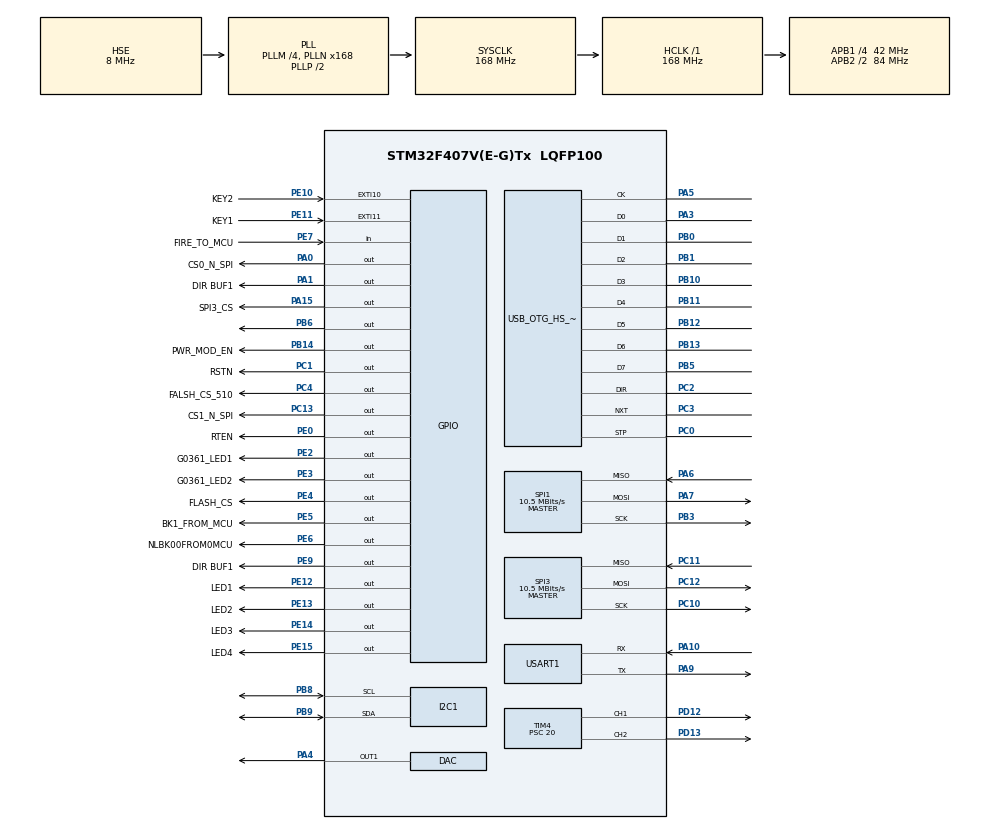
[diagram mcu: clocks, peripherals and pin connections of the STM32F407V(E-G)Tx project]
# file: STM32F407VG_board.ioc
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DAC.DAC_OutputBuffer=DAC_OUTPUTBUFFER_DISABLE
Dma.Request0=SPI1_RX
Dma.Request1=SPI1_TX
Dma.SPI1_RX.0.Direction=DMA_PERIPH_TO_MEMORY
Dma.SPI1_RX.0.FIFOMode=DMA_FIFOMODE_DISABLE
Dma.SPI1_RX.0.Instance=DMA2_Stream2
Dma.SPI1_RX.0.MemDataAlignment=DMA_MDATAALIGN_BYTE
Dma.SPI1_RX.0.MemInc=DMA_MINC_ENABLE
Dma.SPI1_RX.0.Mode=DMA_NORMAL
Dma.SPI1_RX.0.PeriphDataAlignment=DMA_PDATAALIGN_BYTE
Dma.SPI1_RX.0.PeriphInc=DMA_PINC_DISABLE
Dma.SPI1_RX.0.Priority=DMA_PRIORITY_MEDIUM
Dma.SPI1_TX.1.Direction=DMA_MEMORY_TO_PERIPH
Dma.SPI1_TX.1.FIFOMode=DMA_FIFOMODE_DISABLE
Dma.SPI1_TX.1.Instance=DMA2_Stream3
Dma.SPI1_TX.1.MemDataAlignment=DMA_MDATAALIGN_BYTE
Dma.SPI1_TX.1.MemInc=DMA_MINC_ENABLE
Dma.SPI1_TX.1.Mode=DMA_NORMAL
Dma.SPI1_TX.1.PeriphDataAlignment=DMA_PDATAALIGN_BYTE
Dma.SPI1_TX.1.PeriphInc=DMA_PINC_DISABLE
Dma.SPI1_TX.1.Priority=DMA_PRIORITY_MEDIUM
I2C1.I2C_Mode=I2C_Fast
I2C1.OwnAddress=15
IWDG.Prescaler=IWDG_PRESCALER_32
IWDG.Reload=4000
Mcu.Family=STM32F4
Mcu.Name=STM32F407V(E-G)Tx
Mcu.Package=LQFP100
NVIC.DMA2_Stream2_IRQn=true\:0\:0\:false\:false\:true\:false\:true
NVIC.DMA2_Stream3_IRQn=true\:0\:0\:false\:false\:true\:false\:true
NVIC.EXTI15_10_IRQn=true\:4\:0\:true\:false\:true\:true\:true
NVIC.OTG_HS_EP1_IN_IRQn=true\:0\:0\:false\:false\:true\:true\:true
NVIC.OTG_HS_EP1_OUT_IRQn=true\:0\:0\:false\:false\:true\:true\:true
NVIC.OTG_HS_IRQn=true\:0\:0\:false\:false\:true\:false\:true
NVIC.PriorityGroup=NVIC_PRIORITYGROUP_4
NVIC.TIM3_IRQn=true\:0\:0\:false\:false\:true\:true\:true
PA0-WKUP.GPIO_Label=CS0_N_SPI
PA0-WKUP.GPIO_PuPd=GPIO_PULLUP
PA0-WKUP.GPIO_Speed=GPIO_SPEED_FREQ_VERY_HIGH
PA0-WKUP.PinState=GPIO_PIN_SET
PA0-WKUP.Signal=GPIO_Output
PA1.GPIO_Label=DIR BUF1
PA1.GPIO_ModeDefaultOutputPP=GPIO_MODE_OUTPUT_PP
PA1.GPIO_PuPd=GPIO_PULLUP
PA1.GPIO_Speed=GPIO_SPEED_FREQ_VERY_HIGH
PA1.PinState=GPIO_PIN_SET
PA1.Signal=GPIO_Output
PA10.GPIO_Speed=GPIO_SPEED_FREQ_HIGH
PA10.Mode=Asynchronous
PA10.Signal=USART1_RX
PA13.Signal=SYS_JTMS-SWDIO
PA14.Signal=SYS_JTCK-SWCLK
PA15.GPIO_Label=SPI3_CS
PA15.GPIO_PuPd=GPIO_PULLUP
PA15.GPIO_Speed=GPIO_SPEED_FREQ_VERY_HIGH
PA15.PinState=GPIO_PIN_SET
PA15.Signal=GPIO_Output
PA3.Mode=Device_HS
PA3.Signal=USB_OTG_HS_ULPI_D0
PA4.Signal=COMP_DAC1_group
PA5.Mode=Device_HS
PA5.Signal=USB_OTG_HS_ULPI_CK
PA6.GPIO_PuPd=GPIO_PULLUP
PA6.Mode=Full_Duplex_Master
PA6.Signal=SPI1_MISO
PA7.GPIO_PuPd=GPIO_PULLUP
PA7.Mode=Full_Duplex_Master
PA7.Signal=SPI1_MOSI
PA9.GPIO_Speed=GPIO_SPEED_FREQ_HIGH
PA9.Mode=Asynchronous
PA9.Signal=USART1_TX
PB0.Mode=Device_HS
PB0.Signal=USB_OTG_HS_ULPI_D1
PB1.Mode=Device_HS
PB1.Signal=USB_OTG_HS_ULPI_D2
PB10.Mode=Device_HS
PB10.Signal=USB_OTG_HS_ULPI_D3
PB11.Mode=Device_HS
PB11.Signal=USB_OTG_HS_ULPI_D4
PB12.Mode=Device_HS
PB12.Signal=USB_OTG_HS_ULPI_D5
PB13.Mode=Device_HS
PB13.Signal=USB_OTG_HS_ULPI_D6
PB14.GPIO_Label=PWR_MOD_EN
PB14.GPIO_PuPd=GPIO_PULLUP
PB14.GPIO_Speed=GPIO_SPEED_FREQ_VERY_HIGH
PB14.Signal=GPIO_Output
PB3.GPIO_PuPd=GPIO_PULLUP
PB3.Mode=Full_Duplex_Master
PB3.Signal=SPI1_SCK
PB5.Mode=Device_HS
PB5.Signal=USB_OTG_HS_ULPI_D7
PB6.GPIO_ModeDefaultOutputPP=GPIO_MODE_OUTPUT_OD
PB6.GPIO_Speed=GPIO_SPEED_FREQ_VERY_HIGH
PB6.Signal=GPIO_Output
PB8.GPIO_PuPdOD=GPIO_NOPULL
PB8.GPIO_Speed=GPIO_SPEED_FREQ_HIGH
PB8.Mode=I2C
PB8.Signal=I2C1_SCL
PB9.GPIO_PuPdOD=GPIO_NOPULL
PB9.GPIO_Speed=GPIO_SPEED_FREQ_HIGH
PB9.Mode=I2C
PB9.Signal=I2C1_SDA
PC0.Mode=Device_HS
PC0.Signal=USB_OTG_HS_ULPI_STP
PC1.GPIO_Label=RSTN
PC1.GPIO_PuPd=GPIO_PULLUP
PC1.GPIO_Speed=GPIO_SPEED_FREQ_VERY_HIGH
PC1.PinState=GPIO_PIN_SET
PC1.Signal=GPIO_Output
PC10.GPIO_PuPd=GPIO_PULLUP
PC10.Mode=Full_Duplex_Master
PC10.Signal=SPI3_SCK
PC11.GPIO_PuPd=GPIO_PULLUP
PC11.Mode=Full_Duplex_Master
PC11.Signal=SPI3_MISO
PC12.GPIO_PuPd=GPIO_PULLUP
PC12.Mode=Full_Duplex_Master
PC12.Signal=SPI3_MOSI
PC13-ANTI_TAMP.GPIO_Label=CS1_N_SPI
PC13-ANTI_TAMP.GPIO_PuPd=GPIO_PULLUP
PC13-ANTI_TAMP.PinState=GPIO_PIN_SET
PC13-ANTI_TAMP.Signal=GPIO_Output
PC2.Mode=Device_HS
PC2.Signal=USB_OTG_HS_ULPI_DIR
PC3.Mode=Device_HS
PC3.Signal=USB_OTG_HS_ULPI_NXT
PC4.GPIO_Label=FALSH_CS_510
PC4.GPIO_PuPd=GPIO_PULLUP
PC4.GPIO_Speed=GPIO_SPEED_FREQ_VERY_HIGH
PC4.PinState=GPIO_PIN_SET
PC4.Signal=GPIO_Output
PD12.GPIO_PuPd=GPIO_PULLDOWN
PD12.GPIO_Speed=GPIO_SPEED_FREQ_VERY_HIGH
PD12.Signal=S_TIM4_CH1
PD13.GPIO_PuPd=GPIO_PULLDOWN
PD13.GPIO_Speed=GPIO_SPEED_FREQ_VERY_HIGH
PD13.Signal=S_TIM4_CH2
PE0.GPIO_Label=RTEN
PE0.GPIO_ModeDefaultOutputPP=GPIO_MODE_OUTPUT_PP
PE0.GPIO_PuPd=GPIO_PULLUP
PE0.GPIO_Speed=GPIO_SPEED_FREQ_VERY_HIGH
PE0.PinState=GPIO_PIN_SET
PE0.Signal=GPIO_Output
PE10.GPIO_Label=KEY2
PE10.GPIO_ModeDefaultEXTI=GPIO_MODE_IT_FALLING
PE10.GPIO_PuPd=GPIO_PULLUP
PE10.Signal=GPXTI10
PE11.GPIO_Label=KEY1
PE11.GPIO_ModeDefaultEXTI=GPIO_MODE_IT_FALLING
PE11.GPIO_PuPd=GPIO_PULLUP
PE11.Signal=GPXTI11
PE12.GPIO_Label=LED1
PE12.GPIO_PuPd=GPIO_PULLUP
PE12.GPIO_Speed=GPIO_SPEED_FREQ_VERY_HIGH
PE12.PinState=GPIO_PIN_SET
PE12.Signal=GPIO_Output
PE13.GPIO_Label=LED2
PE13.GPIO_PuPd=GPIO_PULLUP
PE13.GPIO_Speed=GPIO_SPEED_FREQ_VERY_HIGH
PE13.PinState=GPIO_PIN_SET
PE13.Signal=GPIO_Output
PE14.GPIO_Label=LED3
PE14.GPIO_PuPd=GPIO_PULLUP
PE14.GPIO_Speed=GPIO_SPEED_FREQ_VERY_HIGH
PE14.Signal=GPIO_Output
PE15.GPIO_Label=LED4
PE15.GPIO_PuPd=GPIO_PULLUP
PE15.GPIO_Speed=GPIO_SPEED_FREQ_VERY_HIGH
PE15.Signal=GPIO_Output
PE2.GPIO_Label=G0361_LED1 
PE2.GPIO_PuPd=GPIO_PULLUP
PE2.GPIO_Speed=GPIO_SPEED_FREQ_VERY_HIGH
PE2.Signal=GPIO_Output
PE3.GPIO_Label=G0361_LED2
PE3.GPIO_PuPd=GPIO_PULLUP
PE3.GPIO_Speed=GPIO_SPEED_FREQ_VERY_HIGH
PE3.Signal=GPIO_Output
PE4.GPIO_Label=FLASH_CS
PE4.GPIO_PuPd=GPIO_PULLUP
PE4.GPIO_Speed=GPIO_SPEED_FREQ_VERY_HIGH
PE4.PinState=GPIO_PIN_SET
PE4.Signal=GPIO_Output
PE5.GPIO_Label=BK1_FROM_MCU
PE5.GPIO_PuPd=GPIO_PULLUP
PE5.GPIO_Speed=GPIO_SPEED_FREQ_VERY_HIGH
PE5.Signal=GPIO_Output
PE6.GPIO_Label=NLBK00FROM0MCU
PE6.GPIO_PuPd=GPIO_PULLUP
PE6.GPIO_Speed=GPIO_SPEED_FREQ_VERY_HIGH
PE6.Signal=GPIO_Output
PE7.GPIO_Label=FIRE_TO_MCU
PE7.GPIO_PuPd=GPIO_NOPULL
PE7.Signal=GPIO_Input
PE9.GPIO_Label=DIR BUF1
PE9.GPIO_PuPd=GPIO_PULLUP
PE9.GPIO_Speed=GPIO_SPEED_FREQ_VERY_HIGH
PE9.Signal=GPIO_Output
PH0-OSC_IN.Mode=HSE-External-Oscillator
PH0-OSC_IN.Signal=RCC_OSC_IN
PH1-OSC_OUT.Mode=HSE-External-Oscillator
PH1-OSC_OUT.Signal=RCC_OSC_OUT
ProjectManager.HeapSize=0x400
ProjectManager.StackSize=0x2000
ProjectManager.TargetToolchain=MDK-ARM V5
RCC.48MHZClocksFreq_Value=84000000
RCC.AHBFreq_Value=168000000
RCC.APB1CLKDivider=RCC_HCLK_DIV4
RCC.APB1Freq_Value=42000000
RCC.APB1TimFreq_Value=84000000
RCC.APB2CLKDivider=RCC_HCLK_DIV2
RCC.APB2Freq_Value=84000000
RCC.APB2TimFreq_Value=168000000
RCC.CortexFreq_Value=168000000
RCC.EnbaleCSS=true
RCC.HCLKFreq_Value=168000000
RCC.HSE_VALUE=8000000
RCC.HSI_VALUE=16000000
RCC.LSE_VALUE=32768
RCC.PLLM=4
RCC.PLLN=168
RCC.PLLSourceVirtual=RCC_PLLSOURCE_HSE
RCC.SYSCLKFreq_VALUE=168000000
RCC.SYSCLKSource=RCC_SYSCLKSOURCE_PLLCLK
RCC.VCOOutputFreq_Value=336000000
SH.COMP_DAC1_group.0=DAC_OUT1,DAC_OUT1
SH.S_TIM4_CH1.0=TIM4_CH1,PWM Generation1 CH1
SH.S_TIM4_CH2.0=TIM4_CH2,PWM Generation2 CH2
SPI1.BaudRatePrescaler=SPI_BAUDRATEPRESCALER_8
SPI1.CalculateBaudRate=10.5 MBits/s
SPI1.Direction=SPI_DIRECTION_2LINES
SPI1.Mode=SPI_MODE_MASTER
SPI1.VirtualType=VM_MASTER
SPI3.BaudRatePrescaler=SPI_BAUDRATEPRESCALER_4
SPI3.CalculateBaudRate=10.5 MBits/s
SPI3.Direction=SPI_DIRECTION_2LINES
SPI3.Mode=SPI_MODE_MASTER
SPI3.VirtualType=VM_MASTER
TIM3.AutoReloadPreload=TIM_AUTORELOAD_PRELOAD_ENABLE
TIM3.Period=999
TIM3.Prescaler=83
TIM4.AutoReloadPreload=TIM_AUTORELOAD_PRELOAD_ENABLE
TIM4.Channel-PWM\ Generation1\ CH1=TIM_CHANNEL_1
TIM4.Channel-PWM\ Generation2\ CH2=TIM_CHANNEL_2
TIM4.Period=399
TIM4.Prescaler=20
USART1.VirtualMode=VM_ASYNC
USB_DEVICE.CLASS_NAME_HS=CDC
USB_DEVICE.PID_CDC_HS=22288
USB_DEVICE.PRODUCT_STRING_CDC_HS=OXI CDC
USB_DEVICE.VirtualMode-CDC_HS=Cdc
USB_DEVICE.VirtualModeHS=Cdc_HS
USB_OTG_HS.VirtualMode-Device_HS=Device_HS
VP_IWDG_VS_IWDG.Mode=IWDG_Activate
VP_TIM3_VS_ClockSourceINT.Mode=Internal
VP_TIM4_VS_ClockSourceINT.Mode=Internal
VP_USB_DEVICE_VS_USB_DEVICE_CDC_HS.Mode=CDC_HS
board=custom

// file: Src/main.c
/* USER CODE BEGIN Header */
/**
  ******************************************************************************
  * @file           : main.c
  * @brief          : Main program body
  ******************************************************************************
  * @attention
  *
  * <h2><center>&copy; Copyright (c) 2019 STMicroelectronics.
  * All rights reserved.</center></h2>
  *
  * This software component is licensed by ST under BSD 3-Clause license,
  * the "License"; You may not use this file except in compliance with the
  * License. You may obtain a copy of the License at:
  *                        opensource.org/licenses/BSD-3-Clause
  *
  ******************************************************************************
  */
/* USER CODE END Header */

#include "main.h"
#include "usb_device.h"

/* USER CODE BEGIN Includes */
#include <stdio.h>
#include "bsp.h"
#include "app_oxi.h"
#include "dev_usb.h"
#include "type.h"
#include "heap_5.h"
#include "usbd_cdc_if.h"
#include "w25qxx.h"

/* USER CODE END Includes */

/* USER CODE BEGIN PD */

typedef struct _TASK_COMPONENTS
{
	uint8_t Run;
	uint16_t Timer;
	uint16_t ItvTimer;
	void (*TaskHook)(void);
}TASK_COMPONENTS;

typedef enum _TASK_LIST
{
	TASK_SEND_CONTINUE_IMAGE,
	TASK_USB_DATA,
	TASK_KEY_SCAN,
	TASK_LED,
	//TASK_IWDG,
	TASKS_MAX
}TASK_LIST;

/* USER CODE END PD */

DAC_HandleTypeDef hdac;

I2C_HandleTypeDef hi2c1;

IWDG_HandleTypeDef hiwdg;

SPI_HandleTypeDef hspi1;
SPI_HandleTypeDef hspi3;
DMA_HandleTypeDef hdma_spi1_rx;
DMA_HandleTypeDef hdma_spi1_tx;

TIM_HandleTypeDef htim3;
TIM_HandleTypeDef htim4;

UART_HandleTypeDef huart1;

/* USER CODE BEGIN PV */

uint32_t g_u32TIM3cont = 0;

/*********(in order to make printf working, adding the code)********/
#ifdef __GNUC__
/* With GCC, small printf (option LD Linker->Libraries->Small printf
   set to 'Yes') calls __io_putchar() */
#define PUTCHAR_PROTOTYPE int __io_putchar(int ch)
#else
#define PUTCHAR_PROTOTYPE int fputc(int ch, FILE *f)
#endif /* __GNUC__ */
PUTCHAR_PROTOTYPE
{
  HAL_UART_Transmit(&huart1, (uint8_t *)&ch, 1, 0xFFFF);
  return ch;
}

/* USER CODE END PV */

void SystemClock_Config(void);
static void MX_GPIO_Init(void);
static void MX_DMA_Init(void);
static void MX_USART1_UART_Init(void);
static void MX_TIM3_Init(void);
static void MX_DAC_Init(void);
static void MX_I2C1_Init(void);
static void MX_SPI1_Init(void);
static void MX_SPI3_Init(void);
static void MX_TIM4_Init(void);
static void MX_IWDG_Init(void);

int main(void)
{
  /* USER CODE BEGIN 1 */
  __enable_irq();
  /* USER CODE END 1 */

  /* MCU Configuration--------------------------------------------------------*/

  /* Reset of all peripherals, Initializes the Flash interface and the Systick. */
  HAL_Init();

  /* Configure the system clock */
  SystemClock_Config();

  /* USER CODE BEGIN SysInit */
  mem_init();
  /* USER CODE END SysInit */

  /* Initialize all configured peripherals */
  MX_GPIO_Init();
  MX_DMA_Init();
  MX_USART1_UART_Init();
  MX_TIM3_Init();
  MX_DAC_Init();
  MX_I2C1_Init();
  MX_SPI1_Init();
  MX_SPI3_Init();
  MX_TIM4_Init();
  MX_USB_DEVICE_Init();
  MX_IWDG_Init();

  /* USER CODE BEGIN 2 */
  HAL_TIM_Base_Start_IT(&htim3); 	// TIMER3 ENBALE
  HAL_DAC_Start(&hdac,DAC_CHANNEL_1);
  BSP_Sector8Prasing();
  BSP_VoltageInit(g_u16Vmod1,g_u8Buf,g_u8Vmod2);
  BSP_INA230Init(g_u16Mod1CaliVal,g_u16Mod2CaliVal);
  HAL_Delay(100);
  /* USER CODE END 2 */

  /* Infinite loop */
  /* USER CODE BEGIN WHILE */

  DBG("UART is OK===123456 \r\n");
  DBG("MCU free ram %d \r\n",xPortGetFreeHeapSize());

  while (1)
  {
    /* USER CODE END WHILE */

    /* USER CODE BEGIN 3 */
	IwdgFeed();
	App_Oxi_TestCodeRun();
	App_Oxi_Task();
  }
  /* USER CODE END 3 */
}

void SystemClock_Config(void)
{
  RCC_OscInitTypeDef RCC_OscInitStruct = {0};
  RCC_ClkInitTypeDef RCC_ClkInitStruct = {0};

  /** Configure the main internal regulator output voltage
  */
  __HAL_RCC_PWR_CLK_ENABLE();
  __HAL_PWR_VOLTAGESCALING_CONFIG(PWR_REGULATOR_VOLTAGE_SCALE1);
  /** Initializes the CPU, AHB and APB busses clocks
  */
  RCC_OscInitStruct.OscillatorType = RCC_OSCILLATORTYPE_LSI|RCC_OSCILLATORTYPE_HSE;
  RCC_OscInitStruct.HSEState = RCC_HSE_ON;
  RCC_OscInitStruct.LSIState = RCC_LSI_ON;
  RCC_OscInitStruct.PLL.PLLState = RCC_PLL_ON;
  RCC_OscInitStruct.PLL.PLLSource = RCC_PLLSOURCE_HSE;
  RCC_OscInitStruct.PLL.PLLM = 4;
  RCC_OscInitStruct.PLL.PLLN = 168;
  RCC_OscInitStruct.PLL.PLLP = RCC_PLLP_DIV2;
  RCC_OscInitStruct.PLL.PLLQ = 4;
  if (HAL_RCC_OscConfig(&RCC_OscInitStruct) != HAL_OK)
  {
    Error_Handler();
  }
  /** Initializes the CPU, AHB and APB busses clocks
  */
  RCC_ClkInitStruct.ClockType = RCC_CLOCKTYPE_HCLK|RCC_CLOCKTYPE_SYSCLK
                              |RCC_CLOCKTYPE_PCLK1|RCC_CLOCKTYPE_PCLK2;
  RCC_ClkInitStruct.SYSCLKSource = RCC_SYSCLKSOURCE_PLLCLK;
  RCC_ClkInitStruct.AHBCLKDivider = RCC_SYSCLK_DIV1;
  RCC_ClkInitStruct.APB1CLKDivider = RCC_HCLK_DIV4;
  RCC_ClkInitStruct.APB2CLKDivider = RCC_HCLK_DIV2;

  if (HAL_RCC_ClockConfig(&RCC_ClkInitStruct, FLASH_LATENCY_5) != HAL_OK)
  {
    Error_Handler();
  }
  /** Enables the Clock Security System
  */
  HAL_RCC_EnableCSS();
}

static void MX_DAC_Init(void)
{

  DAC_ChannelConfTypeDef sConfig = {0};

  /** DAC Initialization
  */
  hdac.Instance = DAC;
  if (HAL_DAC_Init(&hdac) != HAL_OK)
  {
    Error_Handler();
  }
  /** DAC channel OUT1 config
  */
  sConfig.DAC_Trigger = DAC_TRIGGER_NONE;
  sConfig.DAC_OutputBuffer = DAC_OUTPUTBUFFER_DISABLE;
  if (HAL_DAC_ConfigChannel(&hdac, &sConfig, DAC_CHANNEL_1) != HAL_OK)
  {
    Error_Handler();
  }

}

static void MX_I2C1_Init(void)
{

  hi2c1.Instance = I2C1;
  hi2c1.Init.ClockSpeed = 400000;
  hi2c1.Init.DutyCycle = I2C_DUTYCYCLE_2;
  hi2c1.Init.OwnAddress1 = 30;
  hi2c1.Init.AddressingMode = I2C_ADDRESSINGMODE_7BIT;
  hi2c1.Init.DualAddressMode = I2C_DUALADDRESS_DISABLE;
  hi2c1.Init.OwnAddress2 = 0;
  hi2c1.Init.GeneralCallMode = I2C_GENERALCALL_DISABLE;
  hi2c1.Init.NoStretchMode = I2C_NOSTRETCH_DISABLE;
  if (HAL_I2C_Init(&hi2c1) != HAL_OK)
  {
    Error_Handler();
  }

}

static void MX_IWDG_Init(void)
{

  hiwdg.Instance = IWDG;
  hiwdg.Init.Prescaler = IWDG_PRESCALER_32;
  hiwdg.Init.Reload = 4000;
  if (HAL_IWDG_Init(&hiwdg) != HAL_OK)
  {
    Error_Handler();
  }

}

static void MX_SPI1_Init(void)
{

  /* SPI1 parameter configuration*/
  hspi1.Instance = SPI1;
  hspi1.Init.Mode = SPI_MODE_MASTER;
  hspi1.Init.Direction = SPI_DIRECTION_2LINES;
  hspi1.Init.DataSize = SPI_DATASIZE_8BIT;
  hspi1.Init.CLKPolarity = SPI_POLARITY_LOW;
  hspi1.Init.CLKPhase = SPI_PHASE_1EDGE;
  hspi1.Init.NSS = SPI_NSS_SOFT;
  hspi1.Init.BaudRatePrescaler = SPI_BAUDRATEPRESCALER_8;
  hspi1.Init.FirstBit = SPI_FIRSTBIT_MSB;
  hspi1.Init.TIMode = SPI_TIMODE_DISABLE;
  hspi1.Init.CRCCalculation = SPI_CRCCALCULATION_DISABLE;
  hspi1.Init.CRCPolynomial = 10;
  if (HAL_SPI_Init(&hspi1) != HAL_OK)
  {
    Error_Handler();
  }

}

static void MX_SPI3_Init(void)
{

  /* SPI3 parameter configuration*/
  hspi3.Instance = SPI3;
  hspi3.Init.Mode = SPI_MODE_MASTER;
  hspi3.Init.Direction = SPI_DIRECTION_2LINES;
  hspi3.Init.DataSize = SPI_DATASIZE_8BIT;
  hspi3.Init.CLKPolarity = SPI_POLARITY_LOW;
  hspi3.Init.CLKPhase = SPI_PHASE_1EDGE;
  hspi3.Init.NSS = SPI_NSS_SOFT;
  hspi3.Init.BaudRatePrescaler = SPI_BAUDRATEPRESCALER_4;
  hspi3.Init.FirstBit = SPI_FIRSTBIT_MSB;
  hspi3.Init.TIMode = SPI_TIMODE_DISABLE;
  hspi3.Init.CRCCalculation = SPI_CRCCALCULATION_DISABLE;
  hspi3.Init.CRCPolynomial = 10;
  if (HAL_SPI_Init(&hspi3) != HAL_OK)
  {
    Error_Handler();
  }

}

static void MX_TIM3_Init(void)
{

  TIM_ClockConfigTypeDef sClockSourceConfig = {0};
  TIM_MasterConfigTypeDef sMasterConfig = {0};

  htim3.Instance = TIM3;
  htim3.Init.Prescaler = 83;
  htim3.Init.CounterMode = TIM_COUNTERMODE_UP;
  htim3.Init.Period = 999;
  htim3.Init.ClockDivision = TIM_CLOCKDIVISION_DIV1;
  htim3.Init.AutoReloadPreload = TIM_AUTORELOAD_PRELOAD_ENABLE;
  if (HAL_TIM_Base_Init(&htim3) != HAL_OK)
  {
    Error_Handler();
  }
  sClockSourceConfig.ClockSource = TIM_CLOCKSOURCE_INTERNAL;
  if (HAL_TIM_ConfigClockSource(&htim3, &sClockSourceConfig) != HAL_OK)
  {
    Error_Handler();
  }
  sMasterConfig.MasterOutputTrigger = TIM_TRGO_RESET;
  sMasterConfig.MasterSlaveMode = TIM_MASTERSLAVEMODE_DISABLE;
  if (HAL_TIMEx_MasterConfigSynchronization(&htim3, &sMasterConfig) != HAL_OK)
  {
    Error_Handler();
  }

}

static void MX_TIM4_Init(void)
{

  TIM_ClockConfigTypeDef sClockSourceConfig = {0};
  TIM_MasterConfigTypeDef sMasterConfig = {0};
  TIM_OC_InitTypeDef sConfigOC = {0};

  htim4.Instance = TIM4;
  htim4.Init.Prescaler = 20;
  htim4.Init.CounterMode = TIM_COUNTERMODE_UP;
  htim4.Init.Period = 399;
  htim4.Init.ClockDivision = TIM_CLOCKDIVISION_DIV1;
  htim4.Init.AutoReloadPreload = TIM_AUTORELOAD_PRELOAD_ENABLE;
  if (HAL_TIM_Base_Init(&htim4) != HAL_OK)
  {
    Error_Handler();
  }
  sClockSourceConfig.ClockSource = TIM_CLOCKSOURCE_INTERNAL;
  if (HAL_TIM_ConfigClockSource(&htim4, &sClockSourceConfig) != HAL_OK)
  {
    Error_Handler();
  }
  if (HAL_TIM_PWM_Init(&htim4) != HAL_OK)
  {
    Error_Handler();
  }
  sMasterConfig.MasterOutputTrigger = TIM_TRGO_RESET;
  sMasterConfig.MasterSlaveMode = TIM_MASTERSLAVEMODE_DISABLE;
  if (HAL_TIMEx_MasterConfigSynchronization(&htim4, &sMasterConfig) != HAL_OK)
  {
    Error_Handler();
  }
  sConfigOC.OCMode = TIM_OCMODE_PWM1;
  sConfigOC.Pulse = 0;
  sConfigOC.OCPolarity = TIM_OCPOLARITY_HIGH;
  sConfigOC.OCFastMode = TIM_OCFAST_DISABLE;
  if (HAL_TIM_PWM_ConfigChannel(&htim4, &sConfigOC, TIM_CHANNEL_1) != HAL_OK)
  {
    Error_Handler();
  }
  if (HAL_TIM_PWM_ConfigChannel(&htim4, &sConfigOC, TIM_CHANNEL_2) != HAL_OK)
  {
    Error_Handler();
  }
  /* USER CODE BEGIN TIM4_Init 2 */
  pwm_led_set(1,0);
  pwm_led_set(2,0);

  #if  0
  GPIO_InitTypeDef GPIO_InitStruct = {0};
  	__HAL_RCC_GPIOD_CLK_ENABLE();
		/**TIM4 GPIO Configuration
		PD12     ------> TIM4_CH1
		PD13     ------> TIM4_CH2
		*/
		GPIO_InitStruct.Pin = GPIO_PIN_12|GPIO_PIN_13;
		GPIO_InitStruct.Mode = GPIO_MODE_AF_PP;
		GPIO_InitStruct.Pull = GPIO_PULLUP;
		GPIO_InitStruct.Speed = GPIO_SPEED_FREQ_VERY_HIGH;
		GPIO_InitStruct.Alternate = GPIO_AF2_TIM4;
		HAL_GPIO_Init(GPIOD, &GPIO_InitStruct);

  HAL_TIM_PWM_Start(&htim4,TIM_CHANNEL_1);
  HAL_TIM_PWM_Start(&htim4,TIM_CHANNEL_2);
  #endif

  /* USER CODE END TIM4_Init 2 */
  HAL_TIM_MspPostInit(&htim4);

}

static void MX_USART1_UART_Init(void)
{

  huart1.Instance = USART1;
  huart1.Init.BaudRate = 115200;
  huart1.Init.WordLength = UART_WORDLENGTH_8B;
  huart1.Init.StopBits = UART_STOPBITS_1;
  huart1.Init.Parity = UART_PARITY_NONE;
  huart1.Init.Mode = UART_MODE_TX_RX;
  huart1.Init.HwFlowCtl = UART_HWCONTROL_NONE;
  huart1.Init.OverSampling = UART_OVERSAMPLING_16;
  if (HAL_UART_Init(&huart1) != HAL_OK)
  {
    Error_Handler();
  }

}

static void MX_DMA_Init(void)
{

  /* DMA controller clock enable */
  __HAL_RCC_DMA2_CLK_ENABLE();

  /* DMA interrupt init */
  /* DMA2_Stream2_IRQn interrupt configuration */
  HAL_NVIC_SetPriority(DMA2_Stream2_IRQn, 0, 0);
  HAL_NVIC_EnableIRQ(DMA2_Stream2_IRQn);
  /* DMA2_Stream3_IRQn interrupt configuration */
  HAL_NVIC_SetPriority(DMA2_Stream3_IRQn, 0, 0);
  HAL_NVIC_EnableIRQ(DMA2_Stream3_IRQn);

}

static void MX_GPIO_Init(void)
{
  GPIO_InitTypeDef GPIO_InitStruct = {0};

  /* GPIO Ports Clock Enable */
  __HAL_RCC_GPIOE_CLK_ENABLE();
  __HAL_RCC_GPIOC_CLK_ENABLE();
  __HAL_RCC_GPIOH_CLK_ENABLE();
  __HAL_RCC_GPIOA_CLK_ENABLE();
  __HAL_RCC_GPIOB_CLK_ENABLE();
  __HAL_RCC_GPIOD_CLK_ENABLE();

  /*Configure GPIO pin Output Level */
  HAL_GPIO_WritePin(GPIOE, G0361_LED1_Pin|G0361_LED2_Pin|BK1_FROM_MCU_Pin|NLBK00FROM0MCU_Pin
                          |DIR_BUF1E9_Pin|LED3_Pin|LED4_Pin, GPIO_PIN_RESET);

  /*Configure GPIO pin Output Level */
  HAL_GPIO_WritePin(GPIOE, FLASH_CS_Pin|LED1_Pin|LED2_Pin|RTEN_Pin, GPIO_PIN_SET);

  /*Configure GPIO pin Output Level */
  HAL_GPIO_WritePin(GPIOC, CS1_N_SPI_Pin|RSTN_Pin|FALSH_CS_510_Pin, GPIO_PIN_SET);

  /*Configure GPIO pin Output Level */
  HAL_GPIO_WritePin(GPIOA, CS0_N_SPI_Pin|DIR_BUF1_Pin|SPI3_CS_Pin, GPIO_PIN_SET);

  /*Configure GPIO pin Output Level */
  HAL_GPIO_WritePin(GPIOB, PWR_MOD_EN_Pin|GPIO_PIN_6, GPIO_PIN_RESET);

  /*Configure GPIO pins : G0361_LED1_Pin G0361_LED2_Pin FLASH_CS_Pin BK1_FROM_MCU_Pin
                           NLBK00FROM0MCU_Pin DIR_BUF1E9_Pin LED1_Pin LED2_Pin
                           LED3_Pin LED4_Pin RTEN_Pin */
  GPIO_InitStruct.Pin = G0361_LED1_Pin|G0361_LED2_Pin|FLASH_CS_Pin|BK1_FROM_MCU_Pin
                          |NLBK00FROM0MCU_Pin|DIR_BUF1E9_Pin|LED1_Pin|LED2_Pin
                          |LED3_Pin|LED4_Pin|RTEN_Pin;
  GPIO_InitStruct.Mode = GPIO_MODE_OUTPUT_PP;
  GPIO_InitStruct.Pull = GPIO_PULLUP;
  GPIO_InitStruct.Speed = GPIO_SPEED_FREQ_VERY_HIGH;
  HAL_GPIO_Init(GPIOE, &GPIO_InitStruct);

  /*Configure GPIO pin : CS1_N_SPI_Pin */
  GPIO_InitStruct.Pin = CS1_N_SPI_Pin;
  GPIO_InitStruct.Mode = GPIO_MODE_OUTPUT_PP;
  GPIO_InitStruct.Pull = GPIO_PULLUP;
  GPIO_InitStruct.Speed = GPIO_SPEED_FREQ_LOW;
  HAL_GPIO_Init(CS1_N_SPI_GPIO_Port, &GPIO_InitStruct);

  /*Configure GPIO pins : RSTN_Pin FALSH_CS_510_Pin */
  GPIO_InitStruct.Pin = RSTN_Pin|FALSH_CS_510_Pin;
  GPIO_InitStruct.Mode = GPIO_MODE_OUTPUT_PP;
  GPIO_InitStruct.Pull = GPIO_PULLUP;
  GPIO_InitStruct.Speed = GPIO_SPEED_FREQ_VERY_HIGH;
  HAL_GPIO_Init(GPIOC, &GPIO_InitStruct);

  /*Configure GPIO pins : CS0_N_SPI_Pin DIR_BUF1_Pin SPI3_CS_Pin */
  GPIO_InitStruct.Pin = CS0_N_SPI_Pin|DIR_BUF1_Pin|SPI3_CS_Pin;
  GPIO_InitStruct.Mode = GPIO_MODE_OUTPUT_PP;
  GPIO_InitStruct.Pull = GPIO_PULLUP;
  GPIO_InitStruct.Speed = GPIO_SPEED_FREQ_VERY_HIGH;
  HAL_GPIO_Init(GPIOA, &GPIO_InitStruct);

  /*Configure GPIO pin : FIRE_TO_MCU_Pin */
  GPIO_InitStruct.Pin = FIRE_TO_MCU_Pin;
  GPIO_InitStruct.Mode = GPIO_MODE_INPUT;
  GPIO_InitStruct.Pull = GPIO_NOPULL;
  HAL_GPIO_Init(FIRE_TO_MCU_GPIO_Port, &GPIO_InitStruct);

  /*Configure GPIO pins : KEY2_Pin KEY1_Pin */
  GPIO_InitStruct.Pin = KEY2_Pin|KEY1_Pin;
  GPIO_InitStruct.Mode = GPIO_MODE_IT_FALLING;
  GPIO_InitStruct.Pull = GPIO_PULLUP;
  HAL_GPIO_Init(GPIOE, &GPIO_InitStruct);

  /*Configure GPIO pin : PWR_MOD_EN_Pin */
  GPIO_InitStruct.Pin = PWR_MOD_EN_Pin;
  GPIO_InitStruct.Mode = GPIO_MODE_OUTPUT_PP;
  GPIO_InitStruct.Pull = GPIO_PULLUP;
  GPIO_InitStruct.Speed = GPIO_SPEED_FREQ_VERY_HIGH;
  HAL_GPIO_Init(PWR_MOD_EN_GPIO_Port, &GPIO_InitStruct);

  /*Configure GPIO pin : PB6 */
  GPIO_InitStruct.Pin = GPIO_PIN_6;
  GPIO_InitStruct.Mode = GPIO_MODE_OUTPUT_OD;
  GPIO_InitStruct.Pull = GPIO_NOPULL;
  GPIO_InitStruct.Speed = GPIO_SPEED_FREQ_VERY_HIGH;
  HAL_GPIO_Init(GPIOB, &GPIO_InitStruct);

#if(PLATFORM_TYPE == PLATFORM_6500)
  /*Configure GPIO pin : PB7 as enable calibration mode */
  GPIO_InitStruct.Pin = GPIO_PIN_7;
  GPIO_InitStruct.Mode = GPIO_MODE_OUTPUT_PP;
  GPIO_InitStruct.Pull = GPIO_PULLUP;
  GPIO_InitStruct.Speed = GPIO_SPEED_FREQ_VERY_HIGH;
  HAL_GPIO_Init(GPIOB, &GPIO_InitStruct);
#elif(PLATFORM_TYPE == PLATFORM_4940)
  /* EXTI interrupt init*/
  HAL_NVIC_SetPriority(EXTI15_10_IRQn, 4, 0);
  HAL_NVIC_EnableIRQ(EXTI15_10_IRQn);
#endif

}

void Error_Handler(void)
{
}

/************************ (C) COPYRIGHT STMicroelectronics *****END OF FILE****/
